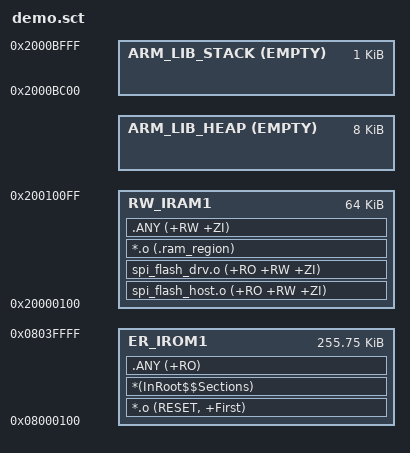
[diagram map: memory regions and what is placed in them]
; *************************************************************
; *** Scatter-Loading Description File generated by uVision ***
; *************************************************************

LR_IROM1 0x08000100 0x3FF00  {    ; load region size_region
  ER_IROM1 0x08000100 0x3FF00  {  ; load address = execution address
   *.o (RESET, +First)
   *(InRoot$$Sections)
   .ANY (+RO)
  }

  RW_IRAM1 0x20000100 0x00010000  {  ; RW data
    spi_flash_host.o (+RO +RW +ZI)
    spi_flash_drv.o  (+RO +RW +ZI)
    *.o              (.ram_region)
    .ANY             (+RW +ZI)
  }

  ARM_LIB_HEAP +0 EMPTY 0x2000 {  ; disable heap,if not use system heap
  }

  ARM_LIB_STACK 0x2000C000 EMPTY -0x400 {
  }
}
